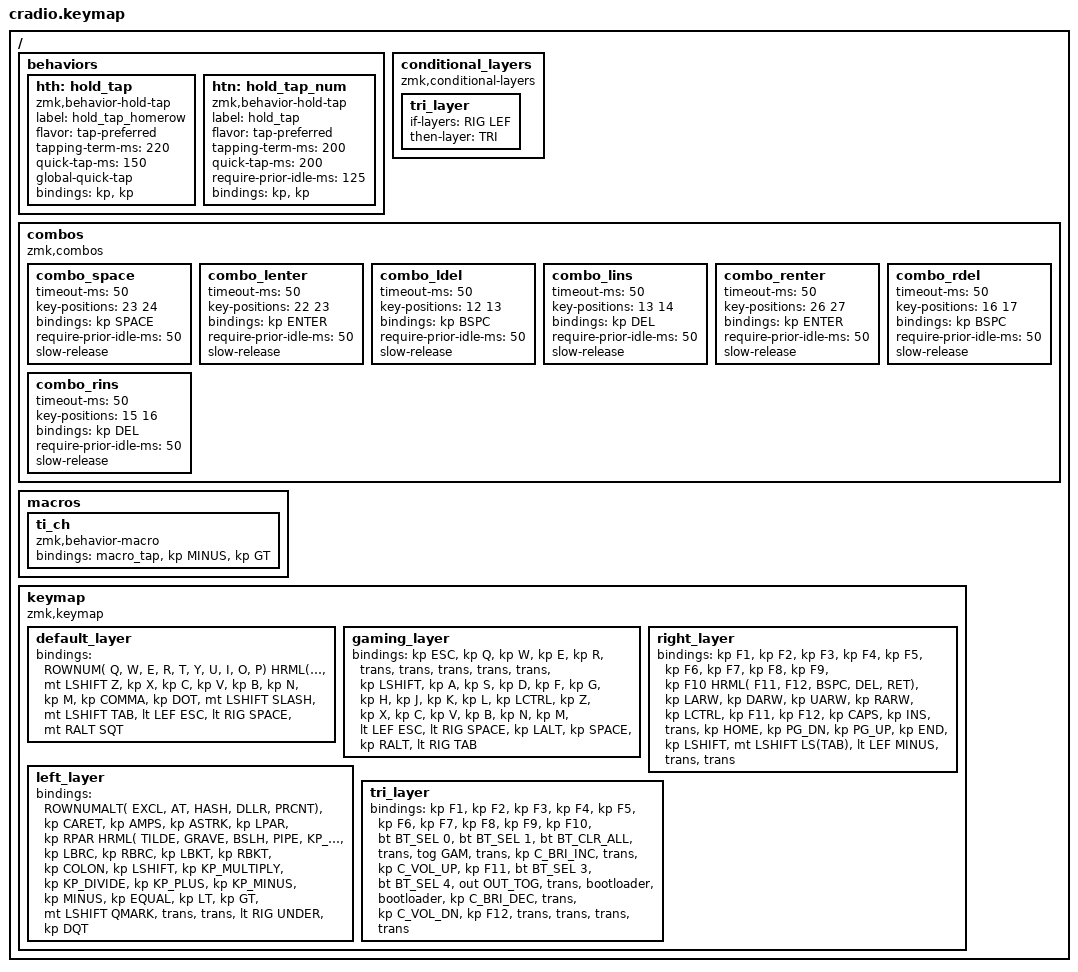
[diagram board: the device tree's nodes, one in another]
// Copyright (c) 2022 The ZMK Contributors
// SPDX-License-Identifier: MIT

#include <behaviors.dtsi>
#include <dt-bindings/zmk/keys.h>
#include <dt-bindings/zmk/bt.h>
#include <dt-bindings/zmk/outputs.h>

// Home row mods macro
#define HRML(k1,k2,k3,k4,k5) &hth LCTRL k1  &hth LCTRL k2  &hth LALT k3  &hth LALT k4  &hth LGUI k5
#define HRMR(k1,k2,k3,k4,k5) &hth LGUI k1  &hth RALT k2  &hth LALT k3 &hth LCTRL k4  &hth LCTRL k5
#define ROWNUM(c1,c2,c3,c4,c5,c6,c7,c8,c9,c0) &htn N1 c1  &htn N2 c2  &htn N3 c3  &htn N4 c4  &htn N5 c5  &htn N6 c6  &htn N7 c7  &htn N8 c8  &htn N9 c9  &htn N0 c0
#define ROWNUMALT(c6,c7,c8,c9,c0) &htn N6 c6  &htn N7 c7  &htn N8 c8  &htn N9 c9  &htn N0 c0

#define DEF 0
#define GAM 1
#define RIG 2
#define LEF 3
#define TRI 4

/ {
    behaviors {
        hth: hold_tap {
            label = "hold_tap_homerow";
            compatible = "zmk,behavior-hold-tap";
            #binding-cells = <2>;
            flavor = "tap-preferred";
            tapping-term-ms = <220>;
            quick-tap-ms = <150>;
            global-quick-tap;
            bindings = <&kp>, <&kp>;
        };
        htn: hold_tap_num {
            label = "hold_tap";
            compatible = "zmk,behavior-hold-tap";
            #binding-cells = <2>;
            flavor = "tap-preferred";
            tapping-term-ms = <200>;
            quick-tap-ms = <200>;
            require-prior-idle-ms = <125>;
            bindings = <&kp>, <&kp>;
        };
    };

    conditional_layers {
        compatible = "zmk,conditional-layers";
        tri_layer {
            if-layers = <RIG LEF>;
            then-layer = <TRI>;
        };
    };

    combos {
        compatible = "zmk,combos";
        combo_space {
            timeout-ms = <50>;
            key-positions = <23 24>;
            bindings = <&kp SPACE>;
            require-prior-idle-ms = <50>;
            slow-release;
        };
        combo_lenter {
            timeout-ms = <50>;
            key-positions = <22 23>;
            bindings = <&kp ENTER>;
            require-prior-idle-ms = <50>;
            slow-release;
        };
        combo_ldel {
            timeout-ms = <50>;
            key-positions = <12 13>;
            bindings = <&kp BSPC>;
            require-prior-idle-ms = <50>;
            slow-release;
        };
        combo_lins {
            timeout-ms = <50>;
            key-positions = <13 14>;
            bindings = <&kp DEL>;
            require-prior-idle-ms = <50>;
            slow-release;
        };
        combo_renter {
            timeout-ms = <50>;
            key-positions = <26 27>;
            bindings = <&kp ENTER>;
            require-prior-idle-ms = <50>;
            slow-release;
            
        };
        combo_rdel {
            timeout-ms = <50>;
            key-positions = <16 17>;
            bindings = <&kp BSPC>;
            require-prior-idle-ms = <50>;
            slow-release;
        };
        combo_rins {
            timeout-ms = <50>;
            key-positions = <15 16>;
            bindings = <&kp DEL>;
            require-prior-idle-ms = <50>;
            slow-release;
        };
    };

    macros {
        ti_ch: ti_ch {
            compatible = "zmk,behavior-macro";
            #binding-cells = <0>;
            bindings
                = <&macro_tap &kp MINUS &kp GT>;
        };
    };

    keymap {
        compatible = "zmk,keymap";
        default_layer {
            bindings = <
        //╭──────────┬──────────┬──────────┬──────────┬──────────╮   ╭──────────┬──────────┬──────────┬──────────┬──────────╮
        //│  Q       │  W       │  E       │  R       │  T       │   │  Y       │  U       │  I       │  O       │  P       │
  ROWNUM(    Q,         W,         E,         R,         T,             Y,         U,         I,         O,         P)
        //├──────────┼──────────┼──────────┼──────────┼──────────┤   ├──────────┼──────────┼──────────┼──────────┼──────────┤
        //│  A       │  S       │  D       │  F       │  G       │   │  H       │  J       │  K       │  L       │    ; :   │
            HRML( A,    S,         D,         F,        G)            HRMR( H,      J,        K,           L,      SEMI)
        //├──────────┼──────────┼──────────┼──────────┼──────────┤   ├──────────┼──────────┼──────────┼──────────┼──────────┤
        //│  Z       │  X       │  C       │  V       │  B       │   │  N       │  M       │ , <      │ . >      │ / ?      │
      &mt LSHIFT Z      &kp X      &kp C      &kp V      &kp B          &kp N      &kp M      &kp COMMA  &kp DOT  &mt LSHIFT SLASH
        //╰──────────┴──────────┴──────────┼──────────┼──────────┤   ├──────────┼──────────┼──────────┴──────────┴──────────╯
                                        &mt LSHIFT TAB  &lt LEF ESC  &lt RIG SPACE  &mt RALT SQT
        //                                 ╰──────────┴──────────╯   ╰─────────┴──────────╯
            >;
        };

        gaming_layer {
            bindings = <
        //╭──────────┬──────────┬──────────┬──────────┬──────────╮   ╭──────────┬──────────┬──────────┬──────────┬──────────╮
        //           │  Q       │  W       │  E       │  R       │   │    Y     │  U       │  I       │  O       │  P       │
             &kp ESC    &kp Q      &kp W      &kp E      &kp R         &trans      &trans      &trans    &trans    &trans   
        //├──────────┼──────────┼──────────┼──────────┼──────────┤   ├──────────┼──────────┼──────────┼──────────┼──────────┤
        //           │  A       │  S       │  D       │  F       │   │          │          │          │          │          │ 
           &kp LSHIFT   &kp A    &kp S        &kp D      &kp F          &kp G       &kp H     &kp J    &kp K     &kp L
        //├──────────┼──────────┼──────────┼──────────┼──────────┤   ├──────────┼──────────┼──────────┼──────────┼──────────┤
        //           │  Z       │  X       │  C       │  V       │   │          │          │          │          │          │
            &kp LCTRL  &kp Z      &kp X      &kp C      &kp V        &kp B      &kp N      &kp M   &lt LEF ESC     &lt RIG SPACE 
        //╰──────────┴──────────┴──────────┼──────────┼──────────┤   ├──────────┼──────────┼──────────┴──────────┴──────────╯
                                             &kp LALT  &kp SPACE      &kp RALT  &lt RIG TAB
        //                                 ╰──────────┴──────────╯   ╰──────────┴──────────╯
            >;
        };

        right_layer {
            bindings = <
        //╭──────────┬──────────┬──────────┬──────────┬──────────╮   ╭──────────┬──────────┬──────────┬──────────┬──────────╮
        //│ F1       │  F2      │  F3      │  F4      │  F5      │   │ F6       │ F7        │ F8        │ F9     │   F10    │
            &kp F1    &kp F2     &kp F3     &kp F4     &kp F5          &kp F6     &kp F7     &kp F8     &kp F9      &kp F10
        //├──────────┼──────────┼──────────┼──────────┼──────────┤   ├──────────┼──────────┼──────────┼──────────┼──────────┤
        //│          │          │          │          │          |   |    LEFT  │  DOWN    │  UP      │  RIGHT   │          │
            HRML( F11,     F12,    BSPC,     DEL,       RET)          &kp LARW   &kp DARW   &kp UARW   &kp RARW    &kp LCTRL 
        //├──────────┼──────────┼──────────┼──────────┼──────────┤   ├──────────┼──────────┼──────────┼──────────┼──────────┤
        //│          │          │          │          │          │   │     HOME │PAGE DN   │ PAGE UP  │ END      │          │
            &kp F11     &kp F12    &kp CAPS  &kp INS     &trans      &kp HOME  &kp PG_DN   &kp PG_UP   &kp END    &kp LSHIFT  
        //╰──────────┴──────────┴──────────┼──────────┼──────────┤   ├──────────┼──────────┼──────────┴──────────┴──────────╯
                                    &mt LSHIFT LS(TAB) &lt LEF MINUS     &trans     &trans
        //                                 ╰──────────┴──────────╯   ╰──────────┴──────────╯
            >;
        };

        left_layer {
            bindings = <
        //╭──────────┬──────────┬──────────┬──────────┬──────────╮   ╭──────────┬──────────┬──────────┬──────────┬──────────╮
        //│  !       │  @       │  #       │  $       │  %       │   │  ^       │  &       │  *       │  (       │  )       │
ROWNUMALT(   EXCL,       AT,        HASH,    DLLR,      PRCNT)         &kp CARET  &kp AMPS   &kp ASTRK  &kp LPAR   &kp RPAR
        //├──────────┼──────────┼──────────┼──────────┼──────────┤   ├──────────┼──────────┼──────────┼──────────┼──────────┤
        //│     ~    │  `       │          │          │          │   │   {      │  }       │   [      │     ]    │  :       │
         HRML( TILDE,    GRAVE,    BSLH,      PIPE,   KP_EQUAL)         &kp LBRC   &kp RBRC  &kp LBKT  &kp RBKT   &kp COLON
        //├──────────┼──────────┼──────────┼──────────┼──────────┤   ├────'──────┼──────────┼──────────┼──────────┼─────────┤
        //│          │          │          │          │          │   │      -    │  =       │  <       │   >      │    ?    │
       &kp LSHIFT  &kp KP_MULTIPLY &kp KP_DIVIDE &kp KP_PLUS &kp KP_MINUS &kp MINUS &kp EQUAL &kp LT    &kp GT    &mt LSHIFT QMARK
        //╰──────────┴──────────┴──────────┼──────────┼──────────┤   ├──────────┼──────────┼──────────┴──────────┴──────────╯
                                               &trans   &trans        &lt RIG UNDER &kp DQT
        //                                 ╰──────────┴──────────╯   ╰──────────┴──────────╯
            >;
        };

        tri_layer {
            bindings = <
        //╭──────────┬──────────┬──────────┬───────────┬────────────╮   ╭────────────┬────────────┬──────────┬───────────┬──────────╮
        //│  F1      │  F2      │  F3      │  F4       │ F5      │  │    F6      │    f7      │   f8     │   f9      │  f10     │
            &kp F1     &kp F2     &kp F3     &kp F4     &kp F5            &kp F6      &kp F7        &kp F8     &kp F9      &kp F10 
        //├──────────┼──────────┼──────────┼───────────┼────────────┤   ├────────────┼────────────┼──────────┼───────────┼──────────┤
        //│  BT0     │  BT1     │  F7      │  F8       │ TOGGLE GAME│   │            │ INC BRIGHT │          │  VOL UP   │ f11      │
      &bt BT_SEL 0  &bt BT_SEL 1 &bt BT_CLR_ALL  &trans  &tog GAM         &trans      &kp C_BRI_INC  &trans   &kp C_VOL_UP  &kp F11
        //├──────────┼──────────┼──────────┼───────────┼────────────┤   ├────────────┼────────────┼──────────┼───────────┼──────────┤
        //│  BT3     │  BT4     │ TOGGLEOUT│           │            │   │            │ DEC BRIGHT │          |  VOL DOWN │ f12      │
        &bt BT_SEL 3  &bt BT_SEL 4 &out OUT_TOG  &trans  &bootloader    &bootloader  &kp C_BRI_DEC  &trans   &kp C_VOL_DN &kp F12
        //╰──────────┴──────────┴──────────┼───────────┼────────────┤   ├────────────┼────────────┼──────────┴───────────┴──────────╯
                                                &trans     &trans        &trans     &trans
        //                                  ╰───────────┴──────────╯   ╰──────────┴────────────╯
            >;
        };
    };
};
